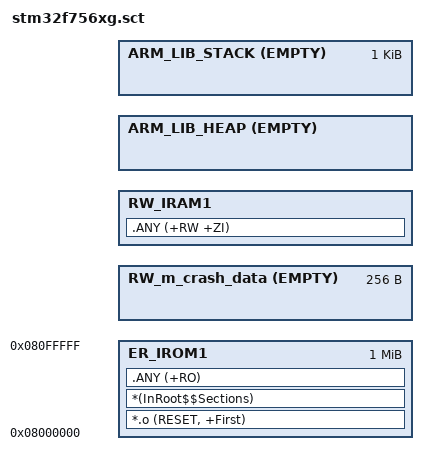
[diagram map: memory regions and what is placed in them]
#! armcc -E
; Scatter-Loading Description File
;
; SPDX-License-Identifier: BSD-3-Clause
;******************************************************************************
;* @attention
;*
;* Copyright (c) 2016-2019 STMicroelectronics.
;* All rights reserved.
;*
;* This software component is licensed by ST under BSD 3-Clause license,
;* the "License"; You may not use this file except in compliance with the
;* License. You may obtain a copy of the License at:
;*                        opensource.org/licenses/BSD-3-Clause
;*
;******************************************************************************
#include "../cmsis_nvic.h"

; STM32F756xG:
; FLASH:   1024K (0x100000) @0x08000000
; SRAM1:    240K (0x3C000)  @0x20010000
; SRAM2:     16K (0x4000)   @0x2004C000
; DTCM-RAM:  64K (0x10000)  @0x20000000
; ITCM-RAM:  16K (0x3FFF)   @0x00000000

#define MBED_ROM_START   0x8000000
#define MBED_ROM_SIZE    0x100000
#define MBED_RAM_START   0x20010000
#define MBED_RAM_SIZE    0x40000
#define MBED_RAM1_START  0x20000000
#define MBED_RAM1_SIZE   0x10000

#if !defined(MBED_APP_START)
  #define MBED_APP_START MBED_ROM_START
#endif

#if !defined(MBED_APP_SIZE)
  #define MBED_APP_SIZE MBED_ROM_SIZE
#endif

#if !defined(MBED_BOOT_STACK_SIZE)
  #define MBED_BOOT_STACK_SIZE 0x400
#endif

#define Stack_Size MBED_BOOT_STACK_SIZE

#define MBED_VECTTABLE_RAM_START    (NVIC_RAM_VECTOR_ADDRESS)
#define MBED_VECTTABLE_RAM_SIZE     (((NVIC_NUM_VECTORS * 4) + 7) AND ~7)

#define MBED_CRASH_REPORT_RAM_START (MBED_VECTTABLE_RAM_START + MBED_VECTTABLE_RAM_SIZE)
#define MBED_CRASH_REPORT_RAM_SIZE  0x100

#define MBED_RAM0_START  (MBED_CRASH_REPORT_RAM_START + MBED_CRASH_REPORT_RAM_SIZE)
#define MBED_RAM0_SIZE   (MBED_RAM_SIZE + MBED_RAM1_SIZE - MBED_VECTTABLE_RAM_SIZE - MBED_CRASH_REPORT_RAM_SIZE)

LR_IROM1 MBED_APP_START MBED_APP_SIZE  {    ; load region size_region

  ER_IROM1 MBED_APP_START MBED_APP_SIZE  {  ; load address = execution address
   *.o (RESET, +First)
   *(InRoot$$Sections)
   .ANY (+RO)
  }

  RW_m_crash_data MBED_CRASH_REPORT_RAM_START EMPTY MBED_CRASH_REPORT_RAM_SIZE { ; RW data
  }

  RW_IRAM1 (MBED_RAM0_START) (MBED_RAM0_SIZE-Stack_Size)  {  ; RW data
   .ANY (+RW +ZI)
  }

  ARM_LIB_HEAP  AlignExpr(+0, 16)  EMPTY  (MBED_RAM0_START + MBED_RAM0_SIZE - Stack_Size - AlignExpr(ImageLimit(RW_IRAM1), 16))  { ; Heap growing up
  }

  ARM_LIB_STACK (MBED_RAM0_START+MBED_RAM0_SIZE) EMPTY -Stack_Size { ; stack
  }
}
